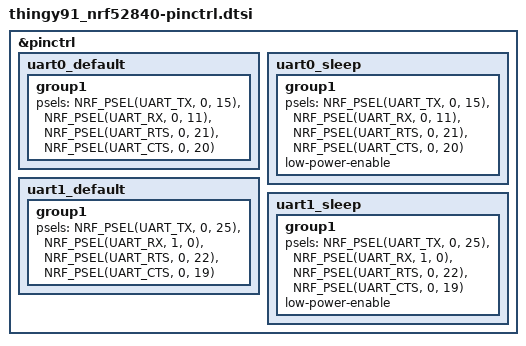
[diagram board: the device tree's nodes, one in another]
/*
 * Copyright (c) 2022 Nordic Semiconductor ASA
 *
 * SPDX-License-Identifier: LicenseRef-Nordic-5-Clause
 */

&pinctrl {
	uart0_default: uart0_default {
		group1 {
			psels = <NRF_PSEL(UART_TX, 0, 15)>,
				<NRF_PSEL(UART_RX, 0, 11)>,
				<NRF_PSEL(UART_RTS, 0, 21)>,
				<NRF_PSEL(UART_CTS, 0, 20)>;
		};
	};

	uart0_sleep: uart0_sleep {
		group1 {
			psels = <NRF_PSEL(UART_TX, 0, 15)>,
				<NRF_PSEL(UART_RX, 0, 11)>,
				<NRF_PSEL(UART_RTS, 0, 21)>,
				<NRF_PSEL(UART_CTS, 0, 20)>;
			low-power-enable;
		};
	};

	uart1_default: uart1_default {
		group1 {
			psels = <NRF_PSEL(UART_TX, 0, 25)>,
				<NRF_PSEL(UART_RX, 1, 0)>,
				<NRF_PSEL(UART_RTS, 0, 22)>,
				<NRF_PSEL(UART_CTS, 0, 19)>;
		};
	};

	uart1_sleep: uart1_sleep {
		group1 {
			psels = <NRF_PSEL(UART_TX, 0, 25)>,
				<NRF_PSEL(UART_RX, 1, 0)>,
				<NRF_PSEL(UART_RTS, 0, 22)>,
				<NRF_PSEL(UART_CTS, 0, 19)>;
			low-power-enable;
		};
	};

};
